# netx90_app register map
File version: 1.0
CPU: CM4 r0p1, little endian, MPU, FPU, 4 interrupt priority bits, 78 interrupts
Registers are 32-bit, read-write, reset 0x0 unless marked. A register's access mark holds for its fields unless they carry their own. Offsets are from the block's base; [hi:lo] are bit positions; {n}, {i} and the like mark numbered series; 'fields as' and 'values as' point back to an identical list.

## cm4_misc_ctrl
Base 0xE0043000
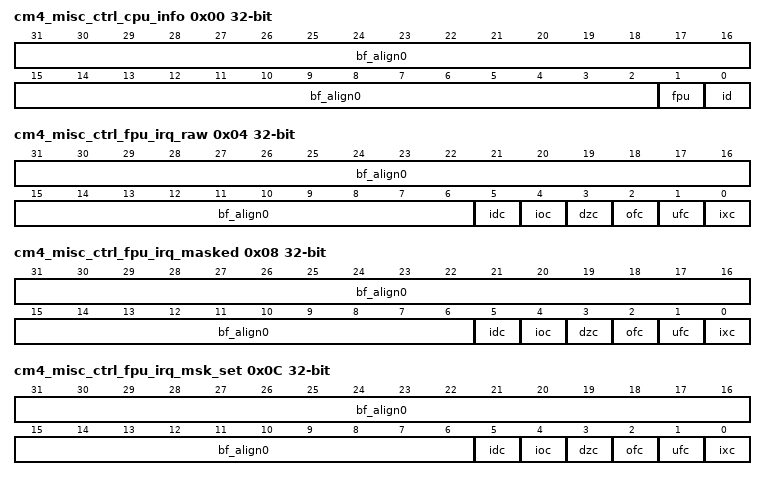
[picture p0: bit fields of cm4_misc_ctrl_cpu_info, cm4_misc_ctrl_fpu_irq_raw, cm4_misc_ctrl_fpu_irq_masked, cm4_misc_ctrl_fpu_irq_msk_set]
0x00 cm4_misc_ctrl_cpu_info ro (reset mask 0x3) — CPU information register Provides a processor identification mechanism to distinguish between Com ARM and App ARM.
  [31:2] bf_align0 — bitField alignment value for aeabi compatibility
  [1] fpu — CPU has FPU If '0' all cm4_misc_ctrl_fpu_* registers have no effect and are read as zero.
  [0] id — CPU identification 0: Com ARM 1: App ARM
0x04 cm4_misc_ctrl_fpu_irq_raw (reset mask 0x3F) — FPU raw IRQ Read access shows status of unmasked IRQs. IRQs are set automatically and reset by writing to this register: Write access with '1' resets the appropriate IRQ. Write access with '0' does not influence this bit. Note: Before clearing an IRQ in this register, the corresponding exception status must be cleared within the FPU. Otherwise the IRQ will be re-asserted immediately.
  [31:6] bf_align0 — bitField alignment value for aeabi compatibility
  [5] idc — Input denormal (ARM-specific exception).
  [4] ioc — Invalid operation (IEEE 754-2008 defined exception).
  [3] dzc — Division by zero (IEEE 754-2008 defined exception).
  [2] ofc — Overflow (IEEE 754-2008 defined exception).
  [1] ufc — Underflow (IEEE 754-2008 defined exception).
  [0] ixc — Inexact (IEEE 754-2008 defined exception).
0x08 cm4_misc_ctrl_fpu_irq_masked ro (reset mask 0x3F) — FPU masked IRQ Shows status of masked IRQs.
  fields as cm4_misc_ctrl_fpu_irq_raw
0x0C cm4_misc_ctrl_fpu_irq_msk_set (reset mask 0x3F) — FPU IRQ mask set The IRQ mask enables interrupt requests for corresponding interrupt sources. As its bits might be changed by different software tasks, the IRQ mask register is not writable directly, but by set and reset masks: Write access with '1' sets interrupt mask bit. Write access with '0' does not influence this bit. Read access shows actual interrupt mask. Attention: Before activating interrupt mask, delete old pending interrupts by writing the same value to cm4_misc_ctrl_fpu_irq_raw.
  fields as cm4_misc_ctrl_fpu_irq_raw
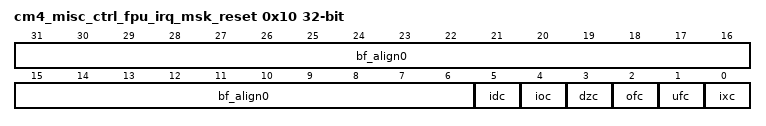
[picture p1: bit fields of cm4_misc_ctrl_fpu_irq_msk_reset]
0x10 cm4_misc_ctrl_fpu_irq_msk_reset (reset mask 0x3F) — FPU IRQ mask reset This is the corresponding reset mask to disable interrupt requests for corresponding interrupt sources: Write access with '1' resets interrupt mask bit. Write access with '0' does not influence this bit. Read access shows actual interrupt mask.
  fields as cm4_misc_ctrl_fpu_irq_raw

## hash_ctx_sha
Base 0xFF080100
{0x0+8i} hash_ctx_sha_w{i}_0 (i=0..14) — SHA context register w{i} part 0
  [31:0] val — Register w{i} part 0 value
{0x4+8i} hash_ctx_sha_w{i}_1 (i=0..14) — SHA context register w{i} part 1
  [31:0] val — Register w{i} part 1 value
0x78 hash_ctx_sha_wt_0 — SHA context register wt part 0
  [31:0] val — Register wt part 0 value
0x7C hash_ctx_sha_wt_1 — SHA context register wt part 1
  [31:0] val — Register wt part 1 value
0x80 hash_ctx_sha_a_0 — SHA context register a part 0
  [31:0] val — Register a part 0 value
0x84 hash_ctx_sha_a_1 — SHA context register a part 1
  [31:0] val — Register a part 1 value
0x88 hash_ctx_sha_b_0 — SHA context register b part 0
  [31:0] val — Register b part 0 value
0x8C hash_ctx_sha_b_1 — SHA context register b part 1
  [31:0] val — Register b part 1 value
0x90 hash_ctx_sha_c_0 — SHA context register c part 0
  [31:0] val — Register c part 0 value
0x94 hash_ctx_sha_c_1 — SHA context register c part 1
  [31:0] val — Register c part 1 value
0x98 hash_ctx_sha_d_0 — SHA context register d part 0
  [31:0] val — Register d part 0 value
0x9C hash_ctx_sha_d_1 — SHA context register d part 1
  [31:0] val — Register d part 1 value
0xA0 hash_ctx_sha_e_0 — SHA context register e part 0
  [31:0] val — Register e part 0 value
0xA4 hash_ctx_sha_e_1 — SHA context register e part 1
  [31:0] val — Register e part 1 value
0xA8 hash_ctx_sha_f_0 — SHA context register f part 0
  [31:0] val — Register f part 0 value
0xAC hash_ctx_sha_f_1 — SHA context register f part 1
  [31:0] val — Register f part 1 value
0xB0 hash_ctx_sha_g_0 — SHA context register g part 0
  [31:0] val — Register g part 0 value
0xB4 hash_ctx_sha_g_1 — SHA context register g part 1
  [31:0] val — Register g part 1 value
0xB8 hash_ctx_sha_h_0 — SHA context register h part 0
  [31:0] val — Register h part 0 value
0xBC hash_ctx_sha_h_1 — SHA context register h part 1
  [31:0] val — Register h part 1 value
